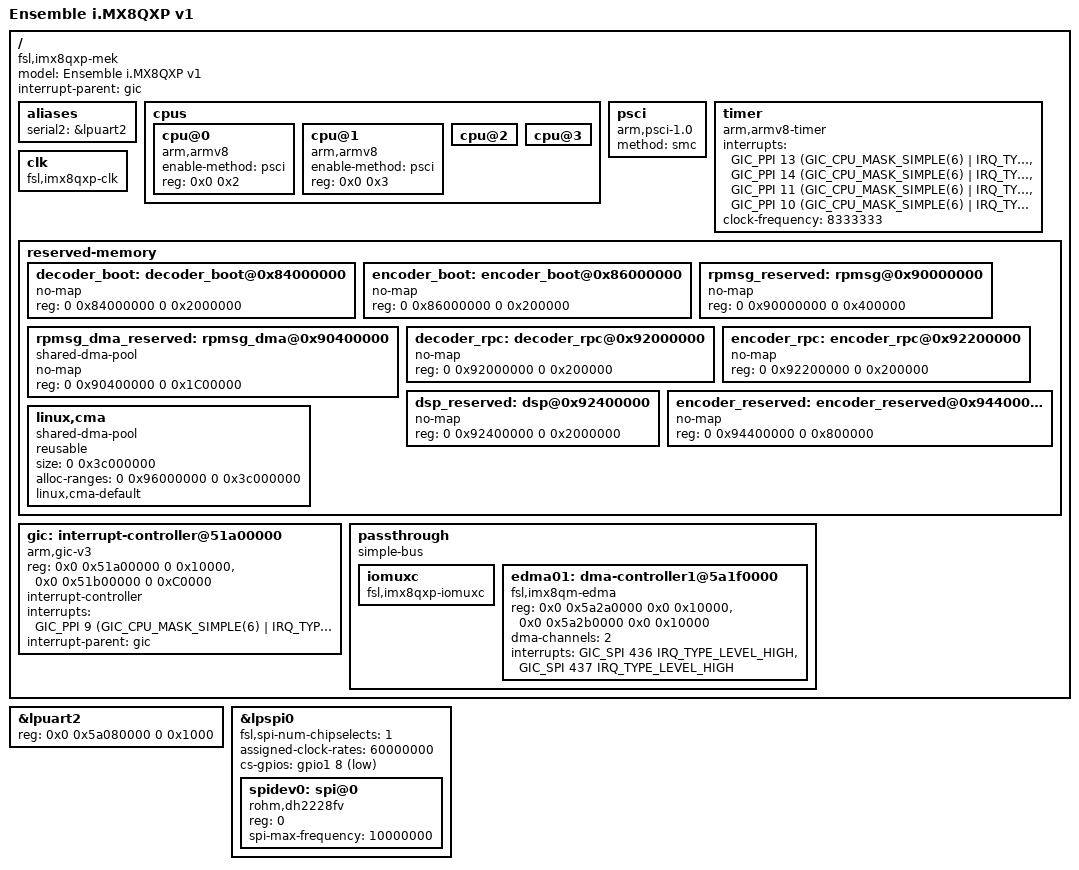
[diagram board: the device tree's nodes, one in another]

/*
 * Copyright 2018 NXP
 *
 * This program is free software; you can redistribute it and/or
 * modify it under the terms of the GNU General Public License
 * as published by the Free Software Foundation; either version 2
 * of the License, or (at your option) any later version.
 *
 * This program is distributed in the hope that it will be useful,
 * but WITHOUT ANY WARRANTY; without even the implied warranty of
 * MERCHANTABILITY or FITNESS FOR A PARTICULAR PURPOSE.  See the
 * GNU General Public License for more details.
 */

 /dts-v1/;

 /memreserve/ 0x80000000 0x1000;


#include <dt-bindings/interrupt-controller/arm-gic.h>
#include <dt-bindings/soc/imx_rsrc.h>
#include <dt-bindings/soc/imx8_hsio.h>
#include <dt-bindings/soc/imx8_pd.h>
#include <dt-bindings/clock/imx8qxp-clock.h>
#include <dt-bindings/input/input.h>
#include <dt-bindings/pinctrl/pads-imx8qxp.h>
#include <dt-bindings/gpio/gpio.h>
#include <dt-bindings/thermal/thermal.h>


/ {
    model = "Ensemble i.MX8QXP v1"; 
	compatible = "fsl,imx8qxp-mek", "fsl,imx8qxp", "xen,xenvm-4.10", "xen,xenvm";
	interrupt-parent = <&gic>;
	#address-cells = <0x2>;
	#size-cells = <0x2>;

	/delete-node/ aliases;


    aliases {
        serial2 = &lpuart2;
    };

	cpus {
		#address-cells = <0x2>;
		#size-cells = <0x0>;

		cpu@0 {
			device_type = "cpu";
			compatible = "arm,armv8";
			enable-method = "psci";
			reg = <0x0 0x2>;
			/delete-property/ cpu-idle-states;
		};

		cpu@1 {
			device_type = "cpu";
			compatible = "arm,armv8";
			enable-method = "psci";
			reg = <0x0 0x3>;
			/delete-property/ cpu-idle-states;
		};

		cpu@2 {
			/delete-property/ cpu-idle-states;
		};

		cpu@3 {
			/delete-property/ cpu-idle-states;
		};
	};

	psci {
			compatible = "arm,psci-1.0";
			method = "smc";
	};

	timer {
		compatible = "arm,armv8-timer";
		interrupts = <GIC_PPI 13 (GIC_CPU_MASK_SIMPLE(6) | IRQ_TYPE_LEVEL_LOW)>, /* Physical Secure */
			     <GIC_PPI 14 (GIC_CPU_MASK_SIMPLE(6) | IRQ_TYPE_LEVEL_LOW)>, /* Physical Non-Secure */
			     <GIC_PPI 11 (GIC_CPU_MASK_SIMPLE(6) | IRQ_TYPE_LEVEL_LOW)>, /* Virtual */
			     <GIC_PPI 10 (GIC_CPU_MASK_SIMPLE(6) | IRQ_TYPE_LEVEL_LOW)>; /* Hypervisor */
		clock-frequency = <8333333>;
	};

	clk: clk {
		compatible = "fsl,imx8qxp-clk";
		#clock-cells = <1>;
	};

	reserved-memory {
		#address-cells = <2>;
		#size-cells = <2>;
		ranges;

		/*
		 * reserved-memory layout
		 * 0x8800_0000 ~ 0x8FFF_FFFF is reserved for M4
		 * Shouldn't be used at A core and Linux side.
		 *
		 */
		decoder_boot: decoder_boot@0x84000000 {
			no-map;
			reg = <0 0x84000000 0 0x2000000>;
		};
		encoder_boot: encoder_boot@0x86000000 {
			no-map;
			reg = <0 0x86000000 0 0x200000>;
		};
		rpmsg_reserved: rpmsg@0x90000000 {
			no-map;
			reg = <0 0x90000000 0 0x400000>;
		};
		rpmsg_dma_reserved:rpmsg_dma@0x90400000 {
			compatible = "shared-dma-pool";
			no-map;
			reg = <0 0x90400000 0 0x1C00000>;
		};
		decoder_rpc: decoder_rpc@0x92000000 {
			no-map;
			reg = <0 0x92000000 0 0x200000>;
		};
		encoder_rpc: encoder_rpc@0x92200000 {
			no-map;
			reg = <0 0x92200000 0 0x200000>;
		};
		dsp_reserved: dsp@0x92400000 {
			no-map;
			reg = <0 0x92400000 0 0x2000000>;
		};
		encoder_reserved: encoder_reserved@0x94400000 {
			no-map;
			reg = <0 0x94400000 0 0x800000>;
		};
		/* global autoconfigured region for contiguous allocations */
		linux,cma {
			compatible = "shared-dma-pool";
			reusable;
			size = <0 0x3c000000>;
			alloc-ranges = <0 0x96000000 0 0x3c000000>;
			linux,cma-default;
		};
	};

	gic: interrupt-controller@51a00000 {
		compatible = "arm,gic-v3";
		reg = <0x0 0x51a00000 0 0x10000>, /* GIC Dist */
		      <0x0 0x51b00000 0 0xC0000>; /* GICR (RD_base + SGI_base) */
		#interrupt-cells = <3>;
		interrupt-controller;
		interrupts = <GIC_PPI 9
			(GIC_CPU_MASK_SIMPLE(6) | IRQ_TYPE_LEVEL_HIGH)>;
		interrupt-parent = <&gic>;
	};

    passthrough {
        compatible = "simple-bus";
        ranges;
        #address-cells = <0x2>;
        #size-cells = <0x2>;
/*
		mu: mu@5d1c0000 {
			compatible = "fsl,imx8-mu";
			reg = <0x0 0x5d1c0000 0x0 0x10000>;
			interrupts = <GIC_SPI 177 IRQ_TYPE_LEVEL_HIGH>;
			interrupt-parent = <&gic>;
			fsl,scu_ap_mu_id = <0>;
			status = "okay";
		};

		mu13: mu13@5d280000 {
			compatible = "fsl,imx8-mu-dsp";
			reg = <0x0 0x5d280000 0x0 0x10000>;
			interrupts = <GIC_SPI 192 IRQ_TYPE_LEVEL_HIGH>;
			fsl,dsp_ap_mu_id = <13>;
			status = "okay";
		};

		mu_m4: mu_m4@37440000 {
			compatible = "fsl,imx8-mu0-vpu-m4";
			reg = <0x0 0x37440000 0x0 0x10000>;
			interrupts = <GIC_SPI 16 IRQ_TYPE_LEVEL_HIGH>;
			fsl,vpu_ap_mu_id = <15>;
			status = "okay";
		};

		mu_m0: mu_m0@2d000000 {
			compatible = "fsl,imx8-mu0-vpu-m0";
			reg = <0x0 0x2d000000 0x0 0x20000>;
			interrupts = <GIC_SPI 469 IRQ_TYPE_LEVEL_HIGH>;
			fsl,vpu_ap_mu_id = <16>;
			status = "okay";
		};

		mu1_m0: mu1_m0@2d020000 {
			compatible = "fsl,imx8-mu1-vpu-m0";
			reg = <0x0 0x2d020000 0x0 0x20000>;
			interrupts = <GIC_SPI 470 IRQ_TYPE_LEVEL_HIGH>;
			fsl,vpu_ap_mu_id = <17>;
			status = "okay";
		};
*/
		iomuxc: iomuxc {
			compatible = "fsl,imx8qxp-iomuxc";
		};      

		#include "fsl-imx8qxp-device.dtsi"

        edma01: dma-controller1@5a1f0000 {
            compatible = "fsl,imx8qm-edma";
            reg = <0x0 0x5a2a0000 0x0 0x10000>, /* channel10 UART1 rx */
                  <0x0 0x5a2b0000 0x0 0x10000>; /* channel11 UART1 tx */
            #dma-cells = <3>;
            dma-channels = <2>;
            interrupts = <GIC_SPI 436 IRQ_TYPE_LEVEL_HIGH>,
                     <GIC_SPI 437 IRQ_TYPE_LEVEL_HIGH>;
            interrupt-names = "edma0-chan10-rx", "edma0-chan11-tx";
            status = "okay";
        };

	};
};

&lpuart2 {
	/delete-property/ interrupt-parent;
	reg = <0x0 0x5a080000 0 0x1000>;
	pinctrl-names = "default";
	//pinctrl-0 = <&pinctrl_lpuart2>;
	status = "okay";
};

/*
&iomuxc {
	imx8qxp-mek {
		pinctrl_lpuart2: lpuart2grp {
			fsl,pins = <
				SC_P_UART2_TX_ADMA_UART2_TX	0x06000020
				SC_P_UART2_RX_ADMA_UART2_RX	0x06000020
			>;
		};
		pinctrl_lpspi0: lpspi0grp {
			fsl,pins = <
				SC_P_SPI0_SCK_ADMA_SPI0_SCK		0x0600004c
				SC_P_SPI0_SDO_ADMA_SPI0_SDO		0x0600004c
				SC_P_SPI0_SDI_ADMA_SPI0_SDI		0x0600004c
			>;
		};

		pinctrl_lpspi0_cs: lpspi0cs {
			fsl,pins = <
				SC_P_SPI0_CS0_LSIO_GPIO1_IO08		0x21
			>;
		};		
	};
};

*/

&lpspi0 {
	fsl,spi-num-chipselects = <1>;
	pinctrl-names = "default";
    //assigned-clock-rates = <20000000>;
    assigned-clock-rates = <60000000>;
	//pinctrl-0 = <&pinctrl_lpspi0 &pinctrl_lpspi0_cs>;
	cs-gpios = <&gpio1 8 GPIO_ACTIVE_LOW>;
	status = "okay";

	spidev0: spi@0 {
        reg = <0>;
		compatible = "rohm,dh2228fv";
		spi-max-frequency = <10000000>;
	};
};

